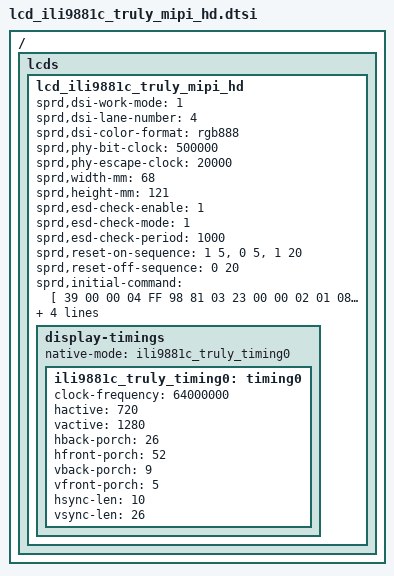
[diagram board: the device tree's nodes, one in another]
// SPDX-License-Identifier: GPL-2.0-only
/*
 * Ili9881c LCD config dtsi file for Unisoc
 *
 * Copyright (C) 2021, Unisoc Inc.
 */
/ {
	fragment {
		target-path = "/";
		__overlay__ {
			lcds {
				lcd_ili9881c_truly_mipi_hd: lcd_ili9881c_truly_mipi_hd {

					sprd,dsi-work-mode = <1>;
					sprd,dsi-lane-number = <4>;
					sprd,dsi-color-format = "rgb888";

					sprd,phy-bit-clock = <500000>;
					sprd,phy-escape-clock = <20000>;

					sprd,width-mm = <68>;
					sprd,height-mm = <121>;

					sprd,esd-check-enable = <1>;
					sprd,esd-check-mode = <1>;
					sprd,esd-check-period = <1000>;

					sprd,reset-on-sequence = <1 5>, <0 5>, <1 20>;
					sprd,reset-off-sequence = <0 20>;

					sprd,initial-command = [
						39 00 00 04 FF 98 81 03
						23 00 00 02 01 08
						23 00 00 02 02 00
						23 00 00 02 03 73
						23 00 00 02 04 73
						23 00 00 02 05 14
						23 00 00 02 06 06
						23 00 00 02 07 02
						23 00 00 02 08 05
						23 00 00 02 09 14
						23 00 00 02 0a 14
						23 00 00 02 0b 00
						23 00 00 02 0c 14
						23 00 00 02 0d 14
						23 00 00 02 0e 00
						23 00 00 02 0f 0c
						23 00 00 02 10 0c
						23 00 00 02 11 0c
						23 00 00 02 12 0c
						23 00 00 02 13 14
						23 00 00 02 14 0c
						23 00 00 02 15 00
						23 00 00 02 16 00
						23 00 00 02 17 00
						23 00 00 02 18 00
						23 00 00 02 19 00
						23 00 00 02 1a 00
						23 00 00 02 1b 00
						23 00 00 02 1c 00
						23 00 00 02 1d 00
						23 00 00 02 1e C8
						23 00 00 02 1f 80
						23 00 00 02 20 02
						23 00 00 02 21 00
						23 00 00 02 22 02
						23 00 00 02 23 00
						23 00 00 02 24 00
						23 00 00 02 25 00
						23 00 00 02 26 00
						23 00 00 02 27 00
						23 00 00 02 28 fb
						23 00 00 02 29 43
						23 00 00 02 2a 00
						23 00 00 02 2b 00
						23 00 00 02 2c 07
						23 00 00 02 2d 07
						23 00 00 02 2e ff
						23 00 00 02 2f ff
						23 00 00 02 30 11
						23 00 00 02 31 00
						23 00 00 02 32 00
						23 00 00 02 33 00
						23 00 00 02 34 84
						23 00 00 02 35 80
						23 00 00 02 36 07
						23 00 00 02 37 00
						23 00 00 02 38 00
						23 00 00 02 39 00
						23 00 00 02 3a 00
						23 00 00 02 3b 00
						23 00 00 02 3c 00
						23 00 00 02 3d 00
						23 00 00 02 3e 00
						23 00 00 02 3f 00
						23 00 00 02 40 00
						23 00 00 02 41 88
						23 00 00 02 42 00
						23 00 00 02 43 80
						23 00 00 02 44 08
						23 00 00 02 50 01
						23 00 00 02 51 23
						23 00 00 02 52 45
						23 00 00 02 53 67
						23 00 00 02 54 89
						23 00 00 02 55 ab
						23 00 00 02 56 01
						23 00 00 02 57 23
						23 00 00 02 58 45
						23 00 00 02 59 67
						23 00 00 02 5a 89
						23 00 00 02 5b ab
						23 00 00 02 5c cd
						23 00 00 02 5d ef
						23 00 00 02 5e 10
						23 00 00 02 5f 02
						23 00 00 02 60 08
						23 00 00 02 61 09
						23 00 00 02 62 10
						23 00 00 02 63 12
						23 00 00 02 64 11
						23 00 00 02 65 13
						23 00 00 02 66 0c
						23 00 00 02 67 02
						23 00 00 02 68 02
						23 00 00 02 69 02
						23 00 00 02 6a 02
						23 00 00 02 6b 02
						23 00 00 02 6c 0e
						23 00 00 02 6d 0d
						23 00 00 02 6e 0f
						23 00 00 02 6f 02
						23 00 00 02 70 02
						23 00 00 02 71 06
						23 00 00 02 72 07
						23 00 00 02 73 02
						23 00 00 02 74 02
						23 00 00 02 75 02
						23 00 00 02 76 07
						23 00 00 02 77 06
						23 00 00 02 78 11
						23 00 00 02 79 13
						23 00 00 02 7a 10
						23 00 00 02 7b 12
						23 00 00 02 7c 0f
						23 00 00 02 7d 02
						23 00 00 02 7e 02
						23 00 00 02 7f 02
						23 00 00 02 80 02
						23 00 00 02 81 02
						23 00 00 02 82 0d
						23 00 00 02 83 0e
						23 00 00 02 84 0c
						23 00 00 02 85 02
						23 00 00 02 86 02
						23 00 00 02 87 09
						23 00 00 02 88 08
						23 00 00 02 89 02
						23 00 00 02 8A 02
						39 00 00 04 FF 98 81 04
						23 00 00 02 6C 15
						23 00 00 02 6E 2d
						23 00 00 02 6F 35
						23 00 00 02 3A A4
						23 00 00 02 8D 14
						23 00 00 02 87 BA
						23 00 00 02 26 76
						23 00 00 02 B2 D1
						23 00 00 02 B5 06
						39 00 00 04 FF 98 81 01
						23 00 00 02 22 3A
						23 00 00 02 31 00
						23 00 00 02 53 56
						23 00 00 02 55 c0
						23 00 00 02 50 b7
						23 00 00 02 51 b7
						23 00 00 02 60 14
						23 00 00 02 61 00
						23 00 00 02 62 19
						23 00 00 02 63 10
						23 00 00 02 A0 00
						23 00 00 02 A1 1c
						23 00 00 02 A2 2b
						23 00 00 02 A3 13
						23 00 00 02 A4 15
						23 00 00 02 A5 29
						23 00 00 02 A6 1d
						23 00 00 02 A7 1e
						23 00 00 02 A8 9a
						23 00 00 02 A9 1d
						23 00 00 02 AA 29
						23 00 00 02 AB 8d
						23 00 00 02 AC 1c
						23 00 00 02 AD 1c
						23 00 00 02 AE 50
						23 00 00 02 AF 25
						23 00 00 02 B0 2a
						23 00 00 02 B1 57
						23 00 00 02 B2 60
						23 00 00 02 B3 28
						23 00 00 02 C0 0c
						23 00 00 02 C1 1c
						23 00 00 02 C2 2b
						23 00 00 02 C3 13
						23 00 00 02 C4 15
						23 00 00 02 C5 29
						23 00 00 02 C6 1d
						23 00 00 02 C7 1e
						23 00 00 02 C8 9a
						23 00 00 02 C9 1d
						23 00 00 02 CA 29
						23 00 00 02 CB 8d
						23 00 00 02 CC 1c
						23 00 00 02 CD 1c
						23 00 00 02 CE 50
						23 00 00 02 CF 25
						23 00 00 02 D0 2a
						23 00 00 02 D1 57
						23 00 00 02 D2 63
						23 00 00 02 D3 28
						39 00 00 04 FF 98 81 00
						23 00 00 02 35 00
						23 78 00 02 11 00
						23 0A 00 02 29 00
						];
					sprd,sleep-in-command = [
						13 0A 00 01 28
						13 78 00 01 10
						];
					sprd,sleep-out-command = [
						13 78 00 01 11
						13 64 00 01 29
						];

					display-timings {
						native-mode = <&ili9881c_truly_timing0>;

						ili9881c_truly_timing0: timing0 {
							clock-frequency = <64000000>;
							hactive = <720>;
							vactive = <1280>;
							hback-porch = <26>;
							hfront-porch = <52>;
							vback-porch = <9>;
							vfront-porch = <5>;
							hsync-len = <10>;
							vsync-len = <26>;
						};
					};
				};
			};
		};
	};
};

